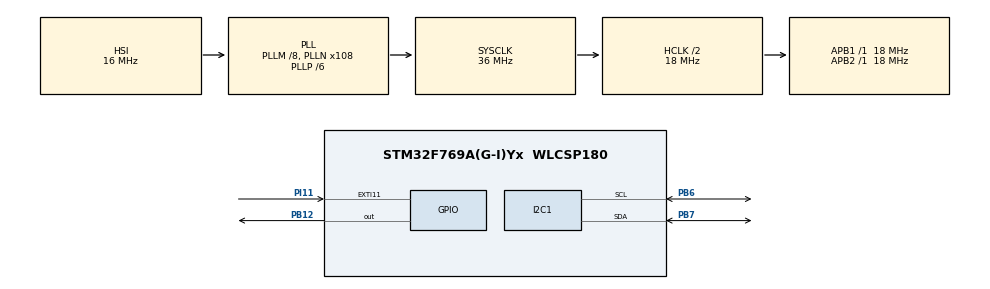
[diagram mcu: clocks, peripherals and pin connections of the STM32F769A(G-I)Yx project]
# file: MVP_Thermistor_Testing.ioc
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I2C1.Timing=0x00404567
Mcu.Family=STM32F7
Mcu.Name=STM32F769A(G-I)Yx
Mcu.Package=WLCSP180
NVIC.EXTI15_10_IRQn=true\:0\:0\:false\:false\:true\:true\:true\:true
NVIC.PriorityGroup=NVIC_PRIORITYGROUP_4
PB12.Signal=GPIO_Output
PB6.Mode=I2C
PB6.Signal=I2C1_SCL
PB7.Mode=I2C
PB7.Signal=I2C1_SDA
PI11.Signal=GPXTI11
ProjectManager.HeapSize=0x200
ProjectManager.StackSize=0x400
ProjectManager.TargetToolchain=STM32CubeIDE
RCC.AHBCLKDivider=RCC_SYSCLK_DIV2
RCC.AHBFreq_Value=18000000
RCC.APB1Freq_Value=18000000
RCC.APB1TimFreq_Value=18000000
RCC.APB2Freq_Value=18000000
RCC.APB2TimFreq_Value=18000000
RCC.CortexFreq_Value=18000000
RCC.HCLKFreq_Value=18000000
RCC.HSE_VALUE=25000000
RCC.HSI_VALUE=16000000
RCC.LSE_VALUE=32768
RCC.PLLM=8
RCC.PLLN=108
RCC.PLLP=RCC_PLLP_DIV6
RCC.SYSCLKFreq_VALUE=36000000
RCC.SYSCLKSource=RCC_SYSCLKSOURCE_PLLCLK
RCC.USBFreq_Value=108000000
RCC.VCOOutputFreq_Value=216000000
board=custom

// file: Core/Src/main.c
/* USER CODE BEGIN Header */
/**
  ******************************************************************************
  * @file           : main.c
  * @brief          : Main program body
  ******************************************************************************
  * @attention
  *
  * Copyright (c) 2022 STMicroelectronics.
  * All rights reserved.
  *
  * This software is licensed under terms that can be found in the LICENSE file
  * in the root directory of this software component.
  * If no LICENSE file comes with this software, it is provided AS-IS.
  *
  ******************************************************************************
  */
/* USER CODE END Header */
#include "main.h"
#include "i2c.h"
#include "gpio.h"

/* USER CODE BEGIN Includes */
#include "thermistor.h"
/* USER CODE END Includes */

/* USER CODE BEGIN PV */
uint8_t status2;
/* USER CODE END PV */

void SystemClock_Config(void);

int main(void)
{

  /* MCU Configuration--------------------------------------------------------*/

  /* Reset of all peripherals, Initializes the Flash interface and the Systick. */
  HAL_Init();

  /* Configure the system clock */
  SystemClock_Config();

  /* Initialize all configured peripherals */
  MX_GPIO_Init();
  MX_I2C1_Init();
  /* USER CODE BEGIN 2 */

  	  mvp_thermistor_init();

  /* USER CODE END 2 */

  /* Infinite loop */
  while (1)
  {

    /* USER CODE BEGIN 3 */

	  mvp_thermistor_process();

  }
  /* USER CODE END 3 */
}

void SystemClock_Config(void)
{
  RCC_OscInitTypeDef RCC_OscInitStruct = {0};
  RCC_ClkInitTypeDef RCC_ClkInitStruct = {0};

  /** Configure the main internal regulator output voltage
  */
  __HAL_RCC_PWR_CLK_ENABLE();
  __HAL_PWR_VOLTAGESCALING_CONFIG(PWR_REGULATOR_VOLTAGE_SCALE3);

  /** Initializes the RCC Oscillators according to the specified parameters
  * in the RCC_OscInitTypeDef structure.
  */
  RCC_OscInitStruct.OscillatorType = RCC_OSCILLATORTYPE_HSI;
  RCC_OscInitStruct.HSIState = RCC_HSI_ON;
  RCC_OscInitStruct.HSICalibrationValue = RCC_HSICALIBRATION_DEFAULT;
  RCC_OscInitStruct.PLL.PLLState = RCC_PLL_ON;
  RCC_OscInitStruct.PLL.PLLSource = RCC_PLLSOURCE_HSI;
  RCC_OscInitStruct.PLL.PLLM = 8;
  RCC_OscInitStruct.PLL.PLLN = 108;
  RCC_OscInitStruct.PLL.PLLP = RCC_PLLP_DIV6;
  RCC_OscInitStruct.PLL.PLLQ = 2;
  RCC_OscInitStruct.PLL.PLLR = 2;
  if (HAL_RCC_OscConfig(&RCC_OscInitStruct) != HAL_OK)
  {
    Error_Handler();
  }

  /** Initializes the CPU, AHB and APB buses clocks
  */
  RCC_ClkInitStruct.ClockType = RCC_CLOCKTYPE_HCLK|RCC_CLOCKTYPE_SYSCLK
                              |RCC_CLOCKTYPE_PCLK1|RCC_CLOCKTYPE_PCLK2;
  RCC_ClkInitStruct.SYSCLKSource = RCC_SYSCLKSOURCE_PLLCLK;
  RCC_ClkInitStruct.AHBCLKDivider = RCC_SYSCLK_DIV2;
  RCC_ClkInitStruct.APB1CLKDivider = RCC_HCLK_DIV1;
  RCC_ClkInitStruct.APB2CLKDivider = RCC_HCLK_DIV1;

  if (HAL_RCC_ClockConfig(&RCC_ClkInitStruct, FLASH_LATENCY_0) != HAL_OK)
  {
    Error_Handler();
  }
}

/* USER CODE BEGIN 4 */
void HAL_GPIO_EXTI_Callback(uint16_t GPIO_Pin)
{
	  HAL_GPIO_WritePin(GPIOB, GPIO_PIN_12, GPIO_PIN_SET);
	  status2 = i2c_write_16bit(buff, status_reg, 2, rst);
}

/* USER CODE END 4 */

void Error_Handler(void)
{
  __disable_irq();
  while (1)
  {
  }
}
